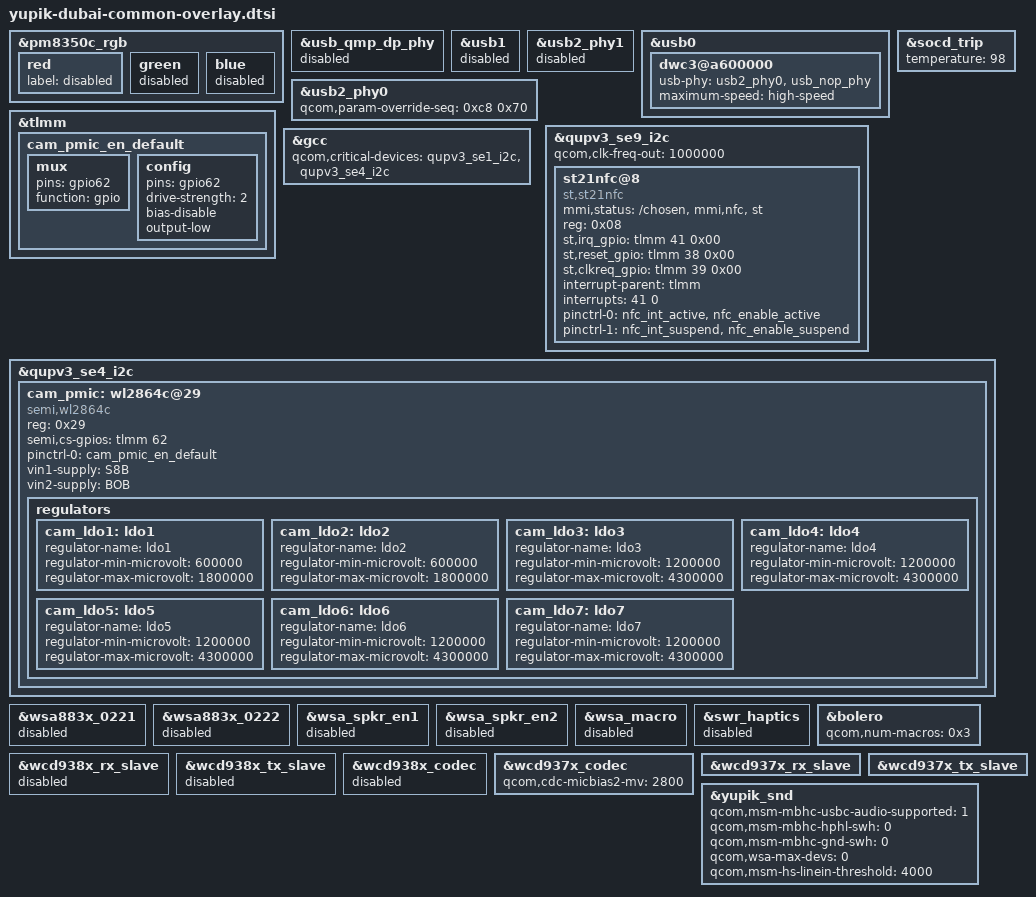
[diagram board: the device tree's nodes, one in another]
/* Copyright (c) 2021, The Linux Foundation. All rights reserved.
 *
 * This program is free software; you can redistribute it and/or modify
 * it under the terms of the GNU General Public License version 2 and
 * only version 2 as published by the Free Software Foundation.
 *
 * This program is distributed in the hope that it will be useful,
 * but WITHOUT ANY WARRANTY; without even the implied warranty of
 * MERCHANTABILITY or FITNESS FOR A PARTICULAR PURPOSE.  See the
 * GNU General Public License for more details.
 */

#include "yupik-moto-common-overlay-pm7250b.dtsi"
#include "yupik-moto-common-charger.dtsi"

&pm8350c_rgb {
	red {
		label = "disabled";
	};
	green {
		status = "disabled";
	};
	blue {
		status = "disabled";
	};
};

&usb_qmp_dp_phy {
	status = "disabled";
};

&usb1 {
	status = "disabled";
};

&usb2_phy1 {
	status = "disabled";
};

&usb0 {
	dwc3@a600000 {
		usb-phy = <&usb2_phy0>, <&usb_nop_phy>;
		maximum-speed = "high-speed";
	};
};

&usb2_phy0 {
	qcom,param-override-seq = <0xc8 0x70>;
};

&socd_trip {
	temperature = <98>;
};

&qupv3_se9_i2c {
	status = "ok";
	qcom,clk-freq-out = <1000000>;
	#address-cells = <1>;
	#size-cells = <0>;

	st21nfc@8 {
		compatible = "st,st21nfc";
		mmi,status = "/chosen", "mmi,nfc", "st";
		status = "ok";
		reg = <0x08>;
                st,irq_gpio = <&tlmm 41 0x00>;
                st,reset_gpio = <&tlmm 38 0x00>;
                st,clkreq_gpio = <&tlmm 39 0x00>;
                interrupt-parent = <&tlmm>;
                interrupts = <41 0>;
                interrupt-names = "nfc_irq";
                pinctrl-names = "nfc_active", "nfc_suspend";
                pinctrl-0 = <&nfc_int_active &nfc_enable_active>;
                pinctrl-1 = <&nfc_int_suspend &nfc_enable_suspend>;
	};
};


&tlmm{
    cam_pmic_en_default: cam_pmic_en_default {
        mux {
            pins = "gpio62";
            function = "gpio";
        };
        config {
            pins = "gpio62";
            drive-strength = <2>;
            bias-disable; /* No PULL */
            output-low;
        };
    };
};

/*
 * Each QUP device that's a parent to PMIC must be listed as a critical device
 * to GCC
 */
&gcc {
    qcom,critical-devices = <&qupv3_se1_i2c>,
                            <&qupv3_se4_i2c>;
};

&qupv3_se4_i2c {
    status = "ok";
    cam_pmic: wl2864c@29 {
        compatible = "semi,wl2864c";
        reg = <0x29>;

        semi,cs-gpios = <&tlmm 62 0>;

        pinctrl-names = "default";
        pinctrl-0 = <&cam_pmic_en_default>;

        vin1-supply = <&S8B>;
        vin2-supply = <&BOB>;

        regulators {
            cam_ldo1: ldo1 {
                regulator-name = "ldo1";
                regulator-min-microvolt = <600000>;
                regulator-max-microvolt = <1800000>;
            };

            cam_ldo2: ldo2 {
                regulator-name = "ldo2";
                regulator-min-microvolt = <600000>;
                regulator-max-microvolt = <1800000>;
            };

            cam_ldo3: ldo3 {
                regulator-name = "ldo3";
                regulator-min-microvolt = <1200000>;
                regulator-max-microvolt = <4300000>;
            };

            cam_ldo4: ldo4 {
                regulator-name = "ldo4";
                regulator-min-microvolt = <1200000>;
                regulator-max-microvolt = <4300000>;
            };

            cam_ldo5: ldo5 {
                regulator-name = "ldo5";
                regulator-min-microvolt = <1200000>;
                regulator-max-microvolt = <4300000>;
            };

            cam_ldo6: ldo6 {
                regulator-name = "ldo6";
                regulator-min-microvolt = <1200000>;
                regulator-max-microvolt = <4300000>;
            };

            cam_ldo7: ldo7 {
                regulator-name = "ldo7";
                regulator-min-microvolt = <1200000>;
                regulator-max-microvolt = <4300000>;
            };
        };
    };
};

&wsa883x_0221 {
	status = "disabled";
};

&wsa883x_0222 {
	status = "disabled";
};

&wsa_spkr_en1 {
	status = "disabled";
};

&wsa_spkr_en2 {
	status = "disabled";
};

&wsa_macro {
	status = "disabled";
};

&swr_haptics {
	status = "disabled";
};

&bolero {
	qcom,num-macros = <0x3>;
};

&wcd938x_rx_slave {
	status = "disabled";
};

&wcd938x_tx_slave {
	status = "disabled";
};

&wcd938x_codec {
	status = "disabled";
};

&wcd937x_codec {
	qcom,cdc-micbias2-mv = <2800>;
	status = "okay";
};

&wcd937x_rx_slave {
	status = "okay";
};

&wcd937x_tx_slave {
	status = "okay";
};

&yupik_snd {
	qcom,msm-mbhc-usbc-audio-supported = <1>;
	qcom,msm-mbhc-hphl-swh = <0>;
	qcom,msm-mbhc-gnd-swh = <0>;

	qcom,wsa-max-devs = <0>;
        qcom,msm-hs-linein-threshold = <4000>;
};
